# nrf54lm20a_enga_application register map
Vendor: Nordic Semiconductor; Series: nrf54l; File version: 1
CPU: CM33 r0p4, little endian, MPU, FPU, 3 interrupt priority bits, 270 interrupts, 4 SAU regions
Registers are 32-bit, read-write, reset 0x0 unless marked. A register's access mark holds for its fields unless they carry their own. Offsets are from the block's base; [hi:lo] are bit positions; lines under a group give offsets from that group; {n}, {i} and the like mark numbered series.

## GLOBAL_VPR00_NS — VPR peripheral registers 0
Base 0x4004C000
Same registers: GLOBAL_VPR00_S 0x5004C000
{0x0+4i} TASKS_TRIGGER[{i}] (i=0..6) wo — Description collection: VPR task [n] register
  [0] TASKS_TRIGGER — VPR task [n] register
    1=Trigger task
{0x80+4i} SUBSCRIBE_TRIGGER[{i}] (i=0..3) — Description collection: Subscribe configuration for task TASKS_TRIGGER[n]
  [31] EN — Subscription enable bit
    0=Disabled (Disable subscription); 1=Enabled (Enable subscription)
{0x100+4i} EVENTS_TRIGGERED[{i}] (i=0..6) — Description collection: VPR event [n] register
  [0] EVENTS_TRIGGERED — VPR event [n] register
    0=NotGenerated (Event not generated); 1=Generated (Event generated)
{0x180+4i} PUBLISH_TRIGGERED[{i}] (i=0..3) — Description collection: Publish configuration for event EVENTS_TRIGGERED[n]
  [31] EN — Publication enable bit
    0=Disabled (Disable publishing); 1=Enabled (Enable publishing)
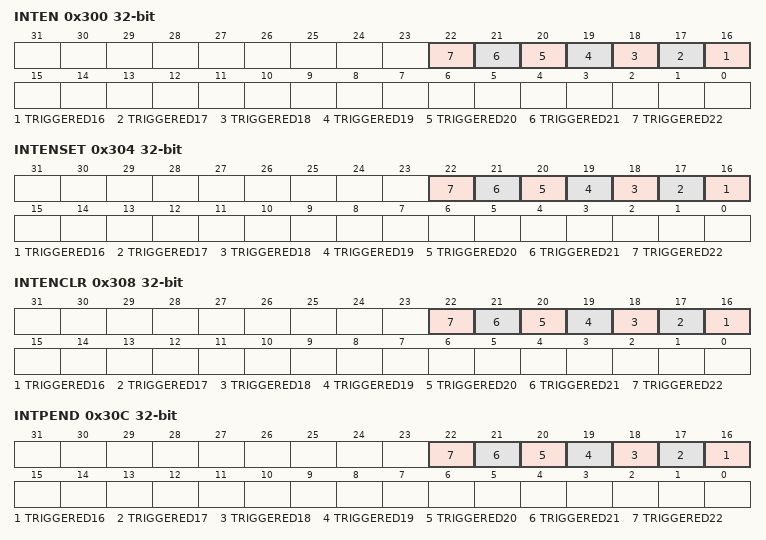
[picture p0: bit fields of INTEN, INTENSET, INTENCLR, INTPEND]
0x300 INTEN — Enable or disable interrupt
  [all] fields
    0=Disabled; 1=Enabled
  [n] TRIGGERED{n} (n=16..22) — Enable or disable interrupt for event TRIGGERED[{n}]
0x304 INTENSET — Enable interrupt
  [all] fields
    on read: 0=Disabled (Read: Disabled); 1=Enabled (Read: Enabled) | on write: 1=Set (Enable)
  [n] TRIGGERED{n} (n=16..22) — Write '1' to enable interrupt for event TRIGGERED[{n}]
0x308 INTENCLR — Disable interrupt
  [all] fields
    on read: 0=Disabled (Read: Disabled); 1=Enabled (Read: Enabled) | on write: 1=Clear (Disable)
  [n] TRIGGERED{n} (n=16..22) — Write '1' to disable interrupt for event TRIGGERED[{n}]
0x30C INTPEND ro — Pending interrupts
  [all] fields
    on read: 0=NotPending (Read: Not pending); 1=Pending (Read: Pending)
  [n] TRIGGERED{n} (n=16..22) — Read pending status of interrupt for event TRIGGERED[{n}]
0x400 DEBUGIF group — Unspecified
  0x10 DATA0 — Abstract Data 0. Read/write data for argument 0
    [31:0] DATA0 — Abstract Data 0
  0x14 DATA1 — Abstract Data 1. Read/write data for argument 1
    [31:0] DATA1 — Abstract Data 1
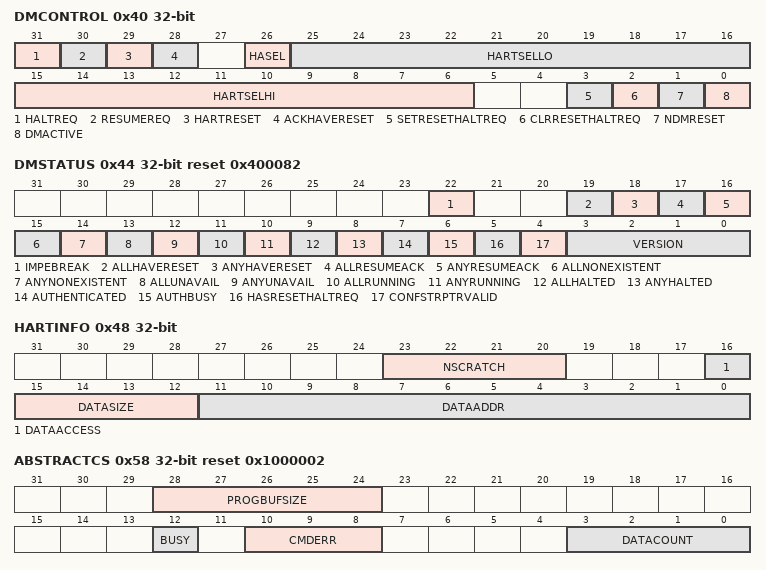
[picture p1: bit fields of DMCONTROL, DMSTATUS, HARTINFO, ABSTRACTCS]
  0x40 DMCONTROL — Debug Module Control
    [31] HALTREQ wo — Halt currently selected harts.
      0=Clears halt request bit for all currently selected harts; 1=Halt (Currently selected harts halted.)
    [30] RESUMEREQ wo — Resume currently selected harts.
      0=No operation when written 0; 1=Resumed (Currently selected harts resumed.)
    [29] HARTRESET — Reset harts.
      0=Deasserted (Reset de-asserted.); 1=Asserted (Reset asserted.)
    [28] ACKHAVERESET wo — Clear the havereset.
      0=No operation when written 0; 1=Clears the havereset for selected harts
    [26] HASEL wo — Definition of currently selected harts.
      0=Single hart selected; 1=Multiple harts selected
    [25:16] HARTSELLO wo — The low 10 bits of hartsel.
    [15:6] HARTSELHI wo — The high 10 bits of hartsel.
    [3] SETRESETHALTREQ wo — Set the halt on reset request.
      0=No operation when written 0; 1=Clear (Sets the halt on reset request)
    [2] CLRRESETHALTREQ wo — Clear the halt on reset request.
      0=No operation when written 0; 1=Clears the halt on reset request
    [1] NDMRESET — Reset signal output from the debug module to the system.
      0=Inactive (Reset inactive); 1=Active (Reset active)
    [0] DMACTIVE — Reset signal for the debug module.
      0=Disabled (Reset the debug module itself); 1=Enabled (Normal operation)
  0x44 DMSTATUS ro reset 0x400082 — Debug Module Status
    [22] IMPEBREAK — Implicit ebreak instruction at the non-existent word immediately after the Program Buffer.
      0=No (No implicit ebreak instruction.); 1=Yes (Implicit ebreak instruction.)
    [19] ALLHAVERESET — All currently selected harts have been reset and reset is not acknowledge
      0=No (Not all of the currently selected harts have been reset and reset is not acknowledge.); 1=Yes (All of the currently selected harts have been reset and reset is not acknowledge.)
    [18] ANYHAVERESET — Any currently selected harts have been reset and reset is not acknowledged.
      0=No (None of the currently selected harts have been reset and reset is not acknowledget.); 1=Yes (Any of the currently selected harts have been reset and reset is not acknowledge.)
    [17] ALLRESUMEACK — All currently selected harts acknowledged last resume
      0=No (Not all of the currently selected harts acknowledged last resume request.); 1=Yes (All of the currently selected harts acknowledged last resume request.)
    [16] ANYRESUMEACK — Any currently selected harts acknowledged last resume request.
      0=No (None of the currently selected harts acknowledged last resume request.); 1=Yes (Any of the currently selected harts acknowledged last resume request.)
    [15] ALLNONEXISTENT — All currently selected harts nonexistent status.
      0=No (Not all of the currently selected harts nonexistent.); 1=Yes (All of the currently selected harts nonexistent.)
    [14] ANYNONEXISTENT — Any currently selected harts nonexistent status.
      0=No (None of the currently selected harts nonexistent.); 1=Yes (Any of the currently selected harts nonexistent.)
    [13] ALLUNAVAIL — All currently selected harts unavailable status.
      0=No (Not all of the currently selected harts unavailable.); 1=Yes (All of the currently selected harts unavailable.)
    [12] ANYUNAVAIL — Any currently selected harts unavailable status.
      0=No (None of the currently selected harts unavailable.); 1=Yes (Any of the currently selected harts unavailable.)
    [11] ALLRUNNING — All currently selected harts running status.
      0=No (Not all of the currently selected harts running.); 1=Yes (All of the currently selected harts running.)
    [10] ANYRUNNING — Any currently selected harts running status.
      0=No (None of the currently selected harts running.); 1=Yes (Any of the currently selected harts running.)
    [9] ALLHALTED — All currently selected harts halted status.
      0=No (Not all of the currently selected harts halted.); 1=Yes (All of the currently selected harts halted.)
    [8] ANYHALTED — Any currently selected harts halted status.
      0=No (None of the currently selected harts halted.); 1=Yes (Any of the currently selected harts halted.)
    [7] AUTHENTICATED — Authentication status.
      0=No (Authentication required before using the debug module.); 1=Yes (Authentication passed.)
    [6] AUTHBUSY — Authentication busy status.
      0=No (The authentication module is ready.); 1=Yes (The authentication module is busy.)
    [5] HASRESETHALTREQ — Halt-on-reset support status.
      0=No (Halt-on-reset is supported.); 1=Yes (Halt-on-reset is not supported.)
    [4] CONFSTRPTRVALID — Configuration string.
      0=NotRelevant (The confstrptr0..confstrptr3 holds information which is not relevant to the configuration string.); 1=Address (The confstrptr0..confstrptr3 holds the address of the configuration string.)
    [3:0] VERSION — Version of the debug module.
      0=NotPresent (Debug module not present.); 1=V011 (There is a Debug Module and it conforms to version 0.11 of this specifcation.); 2=V013 (There is a Debug Module and it conforms to version 0.13 of this specifcation.); 15=NonConform (There is a Debug Module but it does not conform to any available version of the spec.)
  0x48 HARTINFO — Hart Information
    [23:20] NSCRATCH ro — Number of dscratch registers
    [16] DATAACCESS ro
      0=No (The data registers are shadowed in the hart by CSRs. Each CSR is DXLEN bits in size, and corresponds to a single argument.); 1=Yes (The data registers are shadowed in the hart's memory map. Each register takes up 4 bytes in the memory map.)
    [15:12] DATASIZE ro
    [11:0] DATAADDR ro — Data Address
  0x4C HALTSUM1 — Halt Summary 1
    [31:0] HALTSUM1 ro
  0x50 HAWINDOWSEL — Hart Array Window Select
    [14:0] HAWINDOWSEL ro — The high bits of this field may be tied to 0, depending on how large the array mask register is. E.g. on a system with 48 harts only bit 0 of this field may actually be writable.
  0x54 HAWINDOW — Hart Array Window
    [31:0] MASKDATA
  0x58 ABSTRACTCS reset 0x1000002 — Abstract Control and Status
    [28:24] PROGBUFSIZE ro — Size of the Program Buffer, in 32-bit words. Valid sizes are 0 - 1.
    [12] BUSY ro — Abstract command execution status.
      0=NotBusy; 1=Busy (An abstract command is currently being executed. This bit is set as soon as command is written, and is not cleared until that command has completed.)
    [10:8] CMDERR — Command error when the abstract command fails.
      0=NoError; 1=Busy (An abstract command was executing while command, abstractcs, or abstractauto was written, or when one of the data or progbuf registers was read or written. This status is only written if cmderr contains 0); 2=NotSupported (The requested command is notsupported, regardless of whether the hart is running or not.); 3=Exception (An exception occurred while executing the command (e.g. while executing theProgram Buffer).); 4=HaltResume (The abstract command couldn't execute because the hart wasn't in the required state (running/halted). or unavailable.); 5=Bus (The abstract command failed due to abus error (e.g. alignment, access size, or timeout).); 7=Other (The command failed for another reason.)
    [3:0] DATACOUNT ro — Number of data registers that are implemented as part of the abstract command interface. Valid sizes are 1..12.
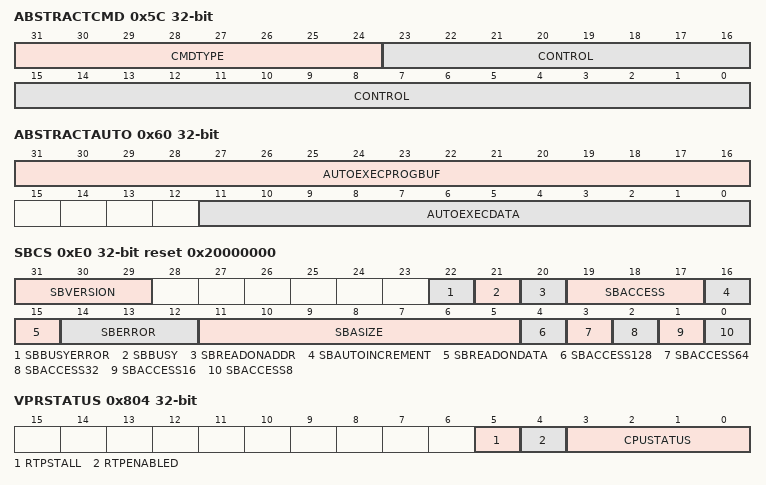
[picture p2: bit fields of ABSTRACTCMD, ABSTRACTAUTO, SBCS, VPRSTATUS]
  0x5C ABSTRACTCMD wo — Abstract command
    [31:24] CMDTYPE — The type determines the overall functionality of this abstract command.
      0=REGACCESS (Register Access Command); 1=QUICKACCESS (Quick Access Command); 2=MEMACCESS (Memory Access Command)
    [23:0] CONTROL — This Field is interpreted in a command specific manner, described for each abstract command.
  0x60 ABSTRACTAUTO — Abstract Command Autoexec
    [31:16] AUTOEXECPROGBUF ro — When a bit in this field is 1, read or write accesses to the corresponding progbuf word cause the command in command to be executed again.
    [11:0] AUTOEXECDATA ro — When a bit in this field is 1, read or write accesses to the corresponding data word cause the command in command to be executed again.
  {0x64+4j} CONFSTRPTR[{j}] (j=0..3) — Description collection: Configuration String Pointer [n]
    [31:0] ADDR ro — Address
  0x74 NEXTDM — Next Debug Module
    [31:0] ADDR ro — Address
  {0x80+4j} PROGBUF[{j}] (j=0..15) — Description collection: Program Buffer [n]
    [31:0] DATA ro
  0xC0 AUTHDATA — Authentication Data
    [31:0] DATA ro
  0xD0 HALTSUM2 — Halt Summary 2
    [31:0] HALTSUM2 ro
  0xD4 HALTSUM3 — Halt Summary 3
    [31:0] HALTSUM3 ro
  0xDC SBADDRESS3 — System Bus Addres 127:96
    [31:0] ADDRESS ro — Accesses bits 127:96 of the physical address in sbaddress (if the system address bus is that wide).
  0xE0 SBCS reset 0x20000000 — System Bus Access Control and Status
    [31:29] SBVERSION ro
      0=version0 (The System Bus interface conforms to mainline drafts of thia RISC-V External Debug Support spec older than 1 January, 2018.); 1=version1 (The System Bus interface conforms to RISC-V External Debug Support version 0.14.0-DRAFT. Other values are reserved for future versions.)
    [22] SBBUSYERROR ro
      0=noerror; 1=error (Debugger access attempted while one in progress.)
    [21] SBBUSY ro
      0=notbusy (System bus master is not busy.); 1=busy (System bus master is busy.)
    [20] SBREADONADDR ro
      1=sbreadonaddr (Every write to sbaddress0 automatically triggers a system bus read at the new address.)
    [19:17] SBACCESS ro
      0=size8 (8-bit.); 1=size16 (16-bit.); 2=size32 (32-bit.); 3=size64 (64-bit.); 4=size128 (128-bit.)
    [16] SBAUTOINCREMENT ro
      1=sbautoincrement (sbaddress is incremented by the access size (in bytes) selected in sbaccess after every system bus access.)
    [15] SBREADONDATA ro
      1=sbreadondata (Every read from sbdata0 automatically triggers a system bus read at the (possibly autoincremented) address.)
    [14:12] SBERROR ro
      0=Normal (There was no bus error.); 1=Timeout (There was a timeout.); 2=Address (A bad address was accessed.); 3=Alignment (There was an alignment error.); 4=Size (An access of unsupported size was requested.); 7=Other
    [11:5] SBASIZE ro — Width of system bus addresses in bits. (0 indicates there is no bus access support.)
    [4] SBACCESS128 ro
      1=sbaccess128 (128-bit system bus accesses are supported.)
    [3] SBACCESS64 ro
      1=sbaccess64 (64-bit system bus accesses are supported.)
    [2] SBACCESS32 ro
      1=sbaccess32 (32-bit system bus accesses are supported.)
    [1] SBACCESS16 ro
      1=sbaccess16 (16-bit system bus accesses are supported.)
    [0] SBACCESS8 ro
      1=sbaccess8 (8-bit system bus accesses are supported.)
  0xE4 SBADDRESS0 — System Bus Addres 31:0
    [31:0] ADDRESS ro — Accesses bits 31:0 of the physical address in sbaddress.
  0xE8 SBADDRESS1 — System Bus Addres 63:32
    [31:0] ADDRESS ro — Accesses bits 63:32 of the physical address in sbaddress (if the system address bus is that wide).
  0xEC SBADDRESS2 — System Bus Addres 95:64
    [31:0] ADDRESS ro — Accesses bits 95:64 of the physical address in sbaddress (if the system address bus is that wide).
  0xF0 SBDATA0 — System Bus Data 31:0
    [31:0] DATA ro — Accesses bits 31:0 of sbdata
  {0xF0+4j} SBDATA{j} (j=1..3) — System Bus Data {32j+31}:{32j}
    [31:0] DATA ro — Accesses bits {32j+31}:{32j} of sbdata (if the system bus is that wide).
  0x100 HALTSUM0 — Halt summary 0
    [31:0] HALTSUM0 ro
0x800 CPURUN — State of the CPU after a core reset
  [0] EN — Controls CPU running state after a core reset.
    0=Stopped (CPU stopped. If this is the CPU state after a core reset, setting this bit will change the CPU state to CPU running.); 1=Running (CPU running. If this is the CPU state after a core reset, clearing this bit will change the CPU state to CPU stopped after a core reset.)
0x804 VPRSTATUS — VPR state information.
  [5] RTPSTALL ro — Stalled waiting for real-time peripheral blocking CSR access, for example WAIT, OUTB with dirty status
  [4] RTPENABLED ro — Mirrors the ENABLERTPERIPH bit in the NORDIC.VPRNORDICCTRL CSR
    0=Disabled (Real-time peripherals disabled); 1=Enabled (Real-time peripherals enabled)
  [3:0] CPUSTATUS ro
    0=WAITING (WAITING (not yet started)); 1=RUNNING; 2=SLEEPING; 3=INTERRUPT (INTERRUPT (in handler)); 4=EXCEPTION_TRAP (EXCEPTION/TRAP (in handler)); 5=ONGOING_RESET; 6=HALTED; 14=ERROR (ERROR (lockup, needs debugging or reset))
0x808 INITPC — Initial value of the PC at CPU start.
